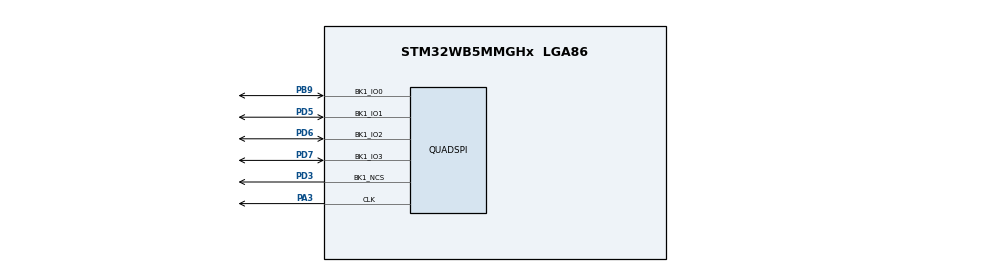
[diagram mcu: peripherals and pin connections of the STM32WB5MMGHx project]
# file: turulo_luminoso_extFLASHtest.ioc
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Mcu.Family=STM32WB
Mcu.Name=STM32WB5MMGHx
Mcu.Package=LGA86
NVIC.PriorityGroup=NVIC_PRIORITYGROUP_4
PA13.Mode=Serial_Wire
PA13.Signal=SYS_JTMS-SWDIO
PA14.Mode=Serial_Wire
PA14.Signal=SYS_JTCK-SWCLK
PA3.Mode=Single Bank 1
PA3.Signal=QUADSPI_CLK
PB9.Mode=Single Bank 1
PB9.Signal=QUADSPI_BK1_IO0
PD3.Mode=Single Bank 1
PD3.Signal=QUADSPI_BK1_NCS
PD5.Mode=Single Bank 1
PD5.Signal=QUADSPI_BK1_IO1
PD6.Mode=Single Bank 1
PD6.Signal=QUADSPI_BK1_IO2
PD7.Mode=Single Bank 1
PD7.Signal=QUADSPI_BK1_IO3
ProjectManager.HeapSize=0x200
ProjectManager.StackSize=0x400
ProjectManager.TargetToolchain=STM32CubeIDE
RCC.ADCFreq_Value=128000000
RCC.AHBFreq_Value=32000000
RCC.APB1Freq_Value=32000000
RCC.APB1TimFreq_Value=32000000
RCC.APB2Freq_Value=32000000
RCC.APB2TimFreq_Value=32000000
RCC.APB3Freq_Value=16000000
RCC.CortexFreq_Value=32000000
RCC.HCLKFreq_Value=32000000
RCC.HSE_VALUE=32000000
RCC.HSI48_VALUE=48000000
RCC.HSI_VALUE=16000000
RCC.MSIClockRange=RCC_MSIRANGE_10
RCC.PLLSourceVirtual=RCC_PLLSOURCE_HSE
RCC.SYSCLKFreq_VALUE=32000000
RCC.USBFreq_Value=128000000
RCC.VCOOutputFreq_Value=256000000
VP_RCC_V_OSC_IN.Mode=HSE-External-Clock-Source
board=custom

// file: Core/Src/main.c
/* USER CODE BEGIN Header */
/**
  ******************************************************************************
  * @file           : main.c
  * @brief          : Main program body
  ******************************************************************************
  * @attention
  *
  * Copyright (c) 2023 STMicroelectronics.
  * All rights reserved.
  *
  * This software is licensed under terms that can be found in the LICENSE file
  * in the root directory of this software component.
  * If no LICENSE file comes with this software, it is provided AS-IS.
  *
  ******************************************************************************
  */
/* USER CODE END Header */
#include "main.h"
#include "quadspi.h"
#include "gpio.h"

/* USER CODE BEGIN Includes */
//flash name is S25FL128SDSMFV001
//mooc  https://www.youtube.com/watch?v=alzv6qg4lH0
//driver https://github.com/STMicroelectronics/stm32-s25fl128s
#include "s25fl128s.h"
/* USER CODE END Includes */

/* USER CODE BEGIN PV */
S25FL128S_Info_t flashmemoryinfo;
uint32_t* memPointer=0x90000000;
uint32_t valuepointedbymemPointer=0;
/* USER CODE END PV */

void SystemClock_Config(void);
void PeriphCommonClock_Config(void);

int main(void)
{

  /* MCU Configuration--------------------------------------------------------*/

  /* Reset of all peripherals, Initializes the Flash interface and the Systick. */
  HAL_Init();

  /* Configure the system clock */
  SystemClock_Config();

/* Configure the peripherals common clocks */
  PeriphCommonClock_Config();

  /* Initialize all configured peripherals */
  MX_GPIO_Init();
  MX_QUADSPI_Init();
  /* USER CODE BEGIN 2 */
  int32_t memstatus=S25FL128S_GetFlashInfo(&flashmemoryinfo);
          memstatus=S25FL128S_ChipErase(&hqspi, S25FL128S_QPI_MODE);
  	  	  memstatus=S25FL128S_WriteEnable(&hqspi, S25FL128S_QPI_MODE);
  		  uint32_t data=0xA;
  		  memstatus=S25FL128S_PageProgram(&hqspi, S25FL128S_QPI_MODE, &data, 0, 4);
  		  memstatus=S25FL128S_WriteDisable(&hqspi, S25FL128S_QPI_MODE);
  	  	  memstatus=S25FL128S_EnableMemoryMappedModeSTR(&hqspi, S25FL128S_QPI_MODE);
  /* USER CODE END 2 */

  /* Infinite loop */
  /* USER CODE BEGIN WHILE */
  while (1)
  {
	  HAL_Delay(1000);
	  valuepointedbymemPointer=*memPointer;
    /* USER CODE END WHILE */

  }
}

void SystemClock_Config(void)
{
  RCC_OscInitTypeDef RCC_OscInitStruct = {0};
  RCC_ClkInitTypeDef RCC_ClkInitStruct = {0};

  /** Configure the main internal regulator output voltage
  */
  __HAL_PWR_VOLTAGESCALING_CONFIG(PWR_REGULATOR_VOLTAGE_SCALE1);

  /** Initializes the RCC Oscillators according to the specified parameters
  * in the RCC_OscInitTypeDef structure.
  */
  RCC_OscInitStruct.OscillatorType = RCC_OSCILLATORTYPE_HSI|RCC_OSCILLATORTYPE_HSE
                              |RCC_OSCILLATORTYPE_MSI;
  RCC_OscInitStruct.HSEState = RCC_HSE_ON;
  RCC_OscInitStruct.HSIState = RCC_HSI_ON;
  RCC_OscInitStruct.MSIState = RCC_MSI_ON;
  RCC_OscInitStruct.HSICalibrationValue = RCC_HSICALIBRATION_DEFAULT;
  RCC_OscInitStruct.MSICalibrationValue = RCC_MSICALIBRATION_DEFAULT;
  RCC_OscInitStruct.MSIClockRange = RCC_MSIRANGE_10;
  RCC_OscInitStruct.PLL.PLLState = RCC_PLL_NONE;
  if (HAL_RCC_OscConfig(&RCC_OscInitStruct) != HAL_OK)
  {
    Error_Handler();
  }

  /** Configure the SYSCLKSource, HCLK, PCLK1 and PCLK2 clocks dividers
  */
  RCC_ClkInitStruct.ClockType = RCC_CLOCKTYPE_HCLK4|RCC_CLOCKTYPE_HCLK2
                              |RCC_CLOCKTYPE_HCLK|RCC_CLOCKTYPE_SYSCLK
                              |RCC_CLOCKTYPE_PCLK1|RCC_CLOCKTYPE_PCLK2;
  RCC_ClkInitStruct.SYSCLKSource = RCC_SYSCLKSOURCE_MSI;
  RCC_ClkInitStruct.AHBCLKDivider = RCC_SYSCLK_DIV1;
  RCC_ClkInitStruct.APB1CLKDivider = RCC_HCLK_DIV1;
  RCC_ClkInitStruct.APB2CLKDivider = RCC_HCLK_DIV1;
  RCC_ClkInitStruct.AHBCLK2Divider = RCC_SYSCLK_DIV1;
  RCC_ClkInitStruct.AHBCLK4Divider = RCC_SYSCLK_DIV1;

  if (HAL_RCC_ClockConfig(&RCC_ClkInitStruct, FLASH_LATENCY_1) != HAL_OK)
  {
    Error_Handler();
  }
}

void PeriphCommonClock_Config(void)
{
  RCC_PeriphCLKInitTypeDef PeriphClkInitStruct = {0};

  /** Initializes the peripherals clock
  */
  PeriphClkInitStruct.PeriphClockSelection = RCC_PERIPHCLK_SMPS;
  PeriphClkInitStruct.SmpsClockSelection = RCC_SMPSCLKSOURCE_HSI;
  PeriphClkInitStruct.SmpsDivSelection = RCC_SMPSCLKDIV_RANGE1;

  if (HAL_RCCEx_PeriphCLKConfig(&PeriphClkInitStruct) != HAL_OK)
  {
    Error_Handler();
  }
}

void Error_Handler(void)
{
  __disable_irq();
  while (1)
  {
  }
}
